AUTOSAR XML (schema 4-2-2)
standard types defined: void, boolean, float32, float64, sint16, sint32, sint64, sint8, uint16, uint32, uint64, uint8, sint16_least, sint32_least, sint8_least, uint16_least, uint32_least, uint8_least, Std_ReturnType
package /AUTOSAR/AUTOSAR_PhysicalUnits/PhysicalDimensions
  76 x physical dimension:
    Amnt1: length-exp=0, mass-exp=0, time-exp=0, current-exp=0, temperature-exp=0, molar-amount-exp=1, luminous-intensity-exp=0  # Quantity of substance
    I1: length-exp=0, mass-exp=0, time-exp=0, current-exp=1, temperature-exp=0, molar-amount-exp=0, luminous-intensity-exp=0  # Electric Current
    Illmn1: length-exp=0, mass-exp=0, time-exp=0, current-exp=0, temperature-exp=0, molar-amount-exp=0, luminous-intensity-exp=1  # Luminous intensity
    Len1: length-exp=1, mass-exp=0, time-exp=0, current-exp=0, temperature-exp=0, molar-amount-exp=0, luminous-intensity-exp=0  # Length
    Len1M1TiNeg2: length-exp=1, mass-exp=1, time-exp=-2, current-exp=0, temperature-exp=0, molar-amount-exp=0, luminous-intensity-exp=0  # Force
    Len1M1TiNeg2INeg2: length-exp=1, mass-exp=1, time-exp=-2, current-exp=-2, temperature-exp=0, molar-amount-exp=0, luminous-intensity-exp=0  # Permeability
    Len1M1TiNeg2_1: length-exp=1, mass-exp=1, time-exp=-2, current-exp=0, temperature-exp=0, molar-amount-exp=0, luminous-intensity-exp=0  # Electrical Energy Consumption
    Len1M1TiNeg3INeg1: length-exp=1, mass-exp=1, time-exp=-3, current-exp=-1, temperature-exp=0, molar-amount-exp=0, luminous-intensity-exp=0  # Electric Field Strength / Electric intensity
    Len1M1TiNeg3TNeg1: length-exp=1, mass-exp=1, time-exp=-3, current-exp=0, temperature-exp=-1, molar-amount-exp=0, luminous-intensity-exp=0  # Thermal Conductivity
    Len1TiNeg1: length-exp=1, mass-exp=0, time-exp=-1, current-exp=0, temperature-exp=0, molar-amount-exp=0, luminous-intensity-exp=0  # Velocity
    Len1TiNeg2: length-exp=1, mass-exp=0, time-exp=-2, current-exp=0, temperature-exp=0, molar-amount-exp=0, luminous-intensity-exp=0  # Acceleration
    Len1TiNeg3: length-exp=1, mass-exp=0, time-exp=-3, current-exp=0, temperature-exp=0, molar-amount-exp=0, luminous-intensity-exp=0  # Acceleration Time Gradient
    Len2: length-exp=2, mass-exp=0, time-exp=0, current-exp=0, temperature-exp=0, molar-amount-exp=0, luminous-intensity-exp=0  # Area
    Len2M1: length-exp=2, mass-exp=1, time-exp=0, current-exp=0, temperature-exp=0, molar-amount-exp=0, luminous-intensity-exp=0  # Moment of Inertia
    Len2M1TiNeg1: length-exp=2, mass-exp=1, time-exp=-1, current-exp=0, temperature-exp=0, molar-amount-exp=0, luminous-intensity-exp=0  # Angular Momentum
    Len2M1TiNeg2: length-exp=2, mass-exp=1, time-exp=-2, current-exp=0, temperature-exp=0, molar-amount-exp=0, luminous-intensity-exp=0  # Torque
    Len2M1TiNeg2AmntNeg1: length-exp=2, mass-exp=1, time-exp=-2, current-exp=0, temperature-exp=0, molar-amount-exp=-1, luminous-intensity-exp=0  # Molar Energy
    Len2M1TiNeg2INeg1: length-exp=2, mass-exp=1, time-exp=-2, current-exp=-1, temperature-exp=0, molar-amount-exp=0, luminous-intensity-exp=0  # Magnetic Flux
    Len2M1TiNeg2INeg2: length-exp=2, mass-exp=1, time-exp=-2, current-exp=-2, temperature-exp=0, molar-amount-exp=0, luminous-intensity-exp=0  # Inductance
    Len2M1TiNeg2TNeg1: length-exp=2, mass-exp=1, time-exp=-2, current-exp=0, temperature-exp=-1, molar-amount-exp=0, luminous-intensity-exp=0  # Heat Capacity
    Len2M1TiNeg2TNeg1AmntNeg1: length-exp=2, mass-exp=1, time-exp=-2, current-exp=0, temperature-exp=-1, molar-amount-exp=-1, luminous-intensity-exp=0  # Molar Heat Capacity
    Len2M1TiNeg2_1: length-exp=2, mass-exp=1, time-exp=-2, current-exp=0, temperature-exp=0, molar-amount-exp=0, luminous-intensity-exp=0  # Energy
    Len2M1TiNeg3: length-exp=2, mass-exp=1, time-exp=-3, current-exp=0, temperature-exp=0, molar-amount-exp=0, luminous-intensity-exp=0  # Torque Time Gradient
    Len2M1TiNeg3INeg1: length-exp=2, mass-exp=1, time-exp=-3, current-exp=-1, temperature-exp=0, molar-amount-exp=0, luminous-intensity-exp=0  # Voltage
    Len2M1TiNeg3INeg2: length-exp=2, mass-exp=1, time-exp=-3, current-exp=-2, temperature-exp=0, molar-amount-exp=0, luminous-intensity-exp=0  # Electric Resistance
    Len2M1TiNeg3_1: length-exp=2, mass-exp=1, time-exp=-3, current-exp=0, temperature-exp=0, molar-amount-exp=0, luminous-intensity-exp=0  # Power
    Len2M1TiNeg4: length-exp=2, mass-exp=1, time-exp=-4, current-exp=0, temperature-exp=0, molar-amount-exp=0, luminous-intensity-exp=0  # Power Time Gradient
    Len2M1TiNeg4INeg1: length-exp=2, mass-exp=1, time-exp=-4, current-exp=-1, temperature-exp=0, molar-amount-exp=0, luminous-intensity-exp=0  # Voltage Time Gradient
    Len2Ti1: length-exp=2, mass-exp=0, time-exp=-1, current-exp=0, temperature-exp=0, molar-amount-exp=0, luminous-intensity-exp=0  # Kinematic Viscosity
    Len2TiNeg2: length-exp=2, mass-exp=0, time-exp=-2, current-exp=0, temperature-exp=0, molar-amount-exp=0, luminous-intensity-exp=0  # Specific Heat
    Len2TiNeg2TNeg1: length-exp=2, mass-exp=0, time-exp=-2, current-exp=0, temperature-exp=-1, molar-amount-exp=0, luminous-intensity-exp=0  # Specific Heat Capacity
    Len2_1: length-exp=2, mass-exp=0, time-exp=0, current-exp=0, temperature-exp=0, molar-amount-exp=0, luminous-intensity-exp=0  # Volume Per Distance / Fuel Consumption
    Len3: length-exp=3, mass-exp=0, time-exp=0, current-exp=0, temperature-exp=0, molar-amount-exp=0, luminous-intensity-exp=0  # Volume
    Len3MNeg1: length-exp=3, mass-exp=-1, time-exp=0, current-exp=0, temperature-exp=0, molar-amount-exp=0, luminous-intensity-exp=0  # Specific Volume
    Len3TiNeg1: length-exp=3, mass-exp=0, time-exp=-1, current-exp=0, temperature-exp=0, molar-amount-exp=0, luminous-intensity-exp=0  # Volumetric Flow
    Len3TiNeg2: length-exp=3, mass-exp=0, time-exp=-2, current-exp=0, temperature-exp=0, molar-amount-exp=0, luminous-intensity-exp=0  # Volumetric Flow Gradient
    LenNeg1: length-exp=-1, mass-exp=0, time-exp=0, current-exp=0, temperature-exp=0, molar-amount-exp=0, luminous-intensity-exp=0  # Inverse Length
    LenNeg1M1TiNeg1: length-exp=-1, mass-exp=1, time-exp=-1, current-exp=0, temperature-exp=0, molar-amount-exp=0, luminous-intensity-exp=0  # Dynamic Viscosity
    LenNeg1M1TiNeg2: length-exp=-1, mass-exp=1, time-exp=-2, current-exp=0, temperature-exp=0, molar-amount-exp=0, luminous-intensity-exp=0  # Pressure
    LenNeg1M1TiNeg2_1: length-exp=-1, mass-exp=1, time-exp=-2, current-exp=0, temperature-exp=0, molar-amount-exp=0, luminous-intensity-exp=0  # Pressure by Angle
    LenNeg1M1TiNeg3: length-exp=-1, mass-exp=1, time-exp=-3, current-exp=0, temperature-exp=0, molar-amount-exp=0, luminous-intensity-exp=0  # Pressure Gradient
    LenNeg2Illmn1: length-exp=-2, mass-exp=0, time-exp=0, current-exp=0, temperature-exp=0, molar-amount-exp=0, luminous-intensity-exp=1  # Illuminance
    LenNeg2MNeg1Ti3I2: length-exp=-2, mass-exp=-1, time-exp=3, current-exp=2, temperature-exp=0, molar-amount-exp=0, luminous-intensity-exp=0  # Electrical Conductance
    LenNeg2MNeg1Ti4I2: length-exp=-2, mass-exp=-1, time-exp=4, current-exp=2, temperature-exp=0, molar-amount-exp=0, luminous-intensity-exp=0  # Capacitance
    LenNeg3Amnt1: length-exp=-3, mass-exp=0, time-exp=0, current-exp=0, temperature-exp=0, molar-amount-exp=1, luminous-intensity-exp=0  # Concentration
    LenNeg3M1: length-exp=-3, mass-exp=1, time-exp=0, current-exp=0, temperature-exp=0, molar-amount-exp=0, luminous-intensity-exp=0  # Mass Density
    LenNeg3MNeg1Ti2I2: length-exp=-3, mass-exp=-1, time-exp=2, current-exp=2, temperature-exp=0, molar-amount-exp=0, luminous-intensity-exp=0  # Electrical Conductivity Gradient
    LenNeg3MNeg1Ti3I2: length-exp=-3, mass-exp=-1, time-exp=3, current-exp=2, temperature-exp=0, molar-amount-exp=0, luminous-intensity-exp=0  # Electrical Conductivity
    LenNeg3Ti1I1: length-exp=-3, mass-exp=0, time-exp=1, current-exp=1, temperature-exp=0, molar-amount-exp=0, luminous-intensity-exp=0  # Electric Charge Density
    LenNeg3Ti1I1_1: length-exp=-3, mass-exp=0, time-exp=1, current-exp=1, temperature-exp=0, molar-amount-exp=0, luminous-intensity-exp=0  # Pressure per Voltage
    LenNeg3TiNeg1Amnt1: length-exp=-3, mass-exp=0, time-exp=-1, current-exp=0, temperature-exp=0, molar-amount-exp=1, luminous-intensity-exp=0  # Reaction Rate
    LenNeg4M1TiNeg1: length-exp=-4, mass-exp=1, time-exp=-1, current-exp=0, temperature-exp=0, molar-amount-exp=0, luminous-intensity-exp=0  # Pressure per Volumetric Flow / Flow Resistance
    M1: length-exp=0, mass-exp=1, time-exp=0, current-exp=0, temperature-exp=0, molar-amount-exp=0, luminous-intensity-exp=0  # Mass
    M1AmntNeg1: length-exp=0, mass-exp=1, time-exp=0, current-exp=0, temperature-exp=0, molar-amount-exp=-1, luminous-intensity-exp=0  # Molar Mass
    M1TiNeg1: length-exp=0, mass-exp=1, time-exp=-1, current-exp=0, temperature-exp=0, molar-amount-exp=0, luminous-intensity-exp=0  # Mass Flow
    M1TiNeg1_1: length-exp=0, mass-exp=1, time-exp=-1, current-exp=0, temperature-exp=0, molar-amount-exp=0, luminous-intensity-exp=0  # Translational Dumping
    M1TiNeg2: length-exp=0, mass-exp=1, time-exp=-2, current-exp=0, temperature-exp=0, molar-amount-exp=0, luminous-intensity-exp=0  # Surface Tension
    M1TiNeg2INeg1: length-exp=0, mass-exp=1, time-exp=-2, current-exp=-1, temperature-exp=0, molar-amount-exp=0, luminous-intensity-exp=0  # Magnetic Flux Density, Magnetic Induction
    M1TiNeg3TNeg1: length-exp=0, mass-exp=1, time-exp=-3, current-exp=0, temperature-exp=-1, molar-amount-exp=0, luminous-intensity-exp=0  # Heat Transfer Coefficient
    NoDimension: length-exp=0, mass-exp=0, time-exp=0, current-exp=0, temperature-exp=0, molar-amount-exp=0, luminous-intensity-exp=0  # Dimensionless
    NoDimension_1: length-exp=0, mass-exp=0, time-exp=0, current-exp=0, temperature-exp=0, molar-amount-exp=0, luminous-intensity-exp=0  # Ratio
    NoDimension_2: length-exp=0, mass-exp=0, time-exp=0, current-exp=0, temperature-exp=0, molar-amount-exp=0, luminous-intensity-exp=0  # Angle
    NoDimension_5: length-exp=0, mass-exp=0, time-exp=0, current-exp=0, temperature-exp=0, molar-amount-exp=0, luminous-intensity-exp=0  # Logarithmic Ratio
    NoDimension_6: length-exp=0, mass-exp=0, time-exp=0, current-exp=0, temperature-exp=0, molar-amount-exp=0, luminous-intensity-exp=0  # Amount of Data
    T1: length-exp=0, mass-exp=0, time-exp=0, current-exp=0, temperature-exp=1, molar-amount-exp=0, luminous-intensity-exp=0  # Absolute Temperature
    T1I1: length-exp=0, mass-exp=0, time-exp=1, current-exp=1, temperature-exp=0, molar-amount-exp=0, luminous-intensity-exp=0  # Electric Charge
    T1_1: length-exp=0, mass-exp=0, time-exp=0, current-exp=0, temperature-exp=1, molar-amount-exp=0, luminous-intensity-exp=0  # Relative Temperature, Temperature Difference
    Ti1: length-exp=0, mass-exp=0, time-exp=1, current-exp=0, temperature-exp=0, molar-amount-exp=0, luminous-intensity-exp=0  # Time
    TiNeg1: length-exp=0, mass-exp=0, time-exp=-1, current-exp=0, temperature-exp=0, molar-amount-exp=0, luminous-intensity-exp=0  # Frequency
    TiNeg1Amnt1: length-exp=0, mass-exp=0, time-exp=-1, current-exp=0, temperature-exp=0, molar-amount-exp=1, luminous-intensity-exp=0  # Catalytic Activity
    TiNeg1I1: length-exp=0, mass-exp=0, time-exp=-1, current-exp=1, temperature-exp=0, molar-amount-exp=0, luminous-intensity-exp=0  # Electric Current Gradient
    TiNeg1T1: length-exp=0, mass-exp=0, time-exp=-1, current-exp=0, temperature-exp=1, molar-amount-exp=0, luminous-intensity-exp=0  # Temperature Gradient
    TiNeg1_1: length-exp=0, mass-exp=0, time-exp=-1, current-exp=0, temperature-exp=0, molar-amount-exp=0, luminous-intensity-exp=0  # Ratio Gradient
    TiNeg1_2: length-exp=0, mass-exp=0, time-exp=-1, current-exp=0, temperature-exp=0, molar-amount-exp=0, luminous-intensity-exp=0  # Rotational Speed
    TiNeg1_3: length-exp=0, mass-exp=0, time-exp=-1, current-exp=0, temperature-exp=0, molar-amount-exp=0, luminous-intensity-exp=0  # Transfer Rate
    TiNeg2: length-exp=0, mass-exp=0, time-exp=-2, current-exp=0, temperature-exp=0, molar-amount-exp=0, luminous-intensity-exp=0  # Rotational Speed Gradient
package /AUTOSAR/AUTOSAR_PhysicalUnits/Units
  164 x unit:
    Ampr: display-name=A, factor-si-to-unit=1, offset-si-to-unit=0, physical-dimension=I1  # Ampere
    AmprPerSec: display-name=A/s, factor-si-to-unit=1, offset-si-to-unit=0, physical-dimension=TiNeg1I1  # Ampere Per Second
    AmprSec: display-name=As, factor-si-to-unit=1, offset-si-to-unit=0, physical-dimension=T1I1  # Amperesecond
    Bar: display-name=bar, factor-si-to-unit=1E-05, offset-si-to-unit=0, physical-dimension=LenNeg1M1TiNeg2
    BarPerSec: display-name=bar/s, factor-si-to-unit=1E-05, offset-si-to-unit=0, physical-dimension=LenNeg1M1TiNeg3  # Bar Per Second
    Bel: display-name=B, factor-si-to-unit=1, offset-si-to-unit=0, physical-dimension=NoDimension_5
    Bit: display-name=bit, factor-si-to-unit=1, offset-si-to-unit=0, physical-dimension=NoDimension_6
    BitPerSec: display-name=bit/s, factor-si-to-unit=1, offset-si-to-unit=0, physical-dimension=TiNeg1_3  # Bit Per Second
    BytPerSec: display-name=Byte/s, factor-si-to-unit=0.125, offset-si-to-unit=0, physical-dimension=TiNeg1_3  # Byte Per Second
    Byte: display-name=Byte, factor-si-to-unit=0.125, offset-si-to-unit=0, physical-dimension=NoDimension_6
    Cd: display-name=cd, factor-si-to-unit=1, offset-si-to-unit=0, physical-dimension=Illmn1  # Candela
    CentiMtr: display-name=cm, factor-si-to-unit=100, offset-si-to-unit=0, physical-dimension=Len1  # Centimeter
    CentiMtrSqd: display-name=cm^2, factor-si-to-unit=10000, offset-si-to-unit=0, physical-dimension=Len2  # Square Centimeter
    Coulomb: display-name=C, factor-si-to-unit=1, offset-si-to-unit=0, physical-dimension=T1I1
    Day: display-name=d, factor-si-to-unit=1.15740740740741E-05, offset-si-to-unit=0, physical-dimension=Ti1
    DeciBel: display-name=dB, factor-si-to-unit=10, offset-si-to-unit=0, physical-dimension=NoDimension_5  # Decibel
    Deg: display-name=°, factor-si-to-unit=360, offset-si-to-unit=0, physical-dimension=NoDimension_2  # Degree
    DegCgrd: display-name=°C, factor-si-to-unit=1, offset-si-to-unit=-273.15, physical-dimension=T1  # Degree Celsius (Absolute Temperature)
    DegPerSec: display-name=°/s, factor-si-to-unit=360, offset-si-to-unit=0, physical-dimension=TiNeg1_2  # Degree Per Sec
    Frd: display-name=F, factor-si-to-unit=1, offset-si-to-unit=0, physical-dimension=LenNeg2MNeg1Ti4I2  # Farad
    Gr: display-name=g, factor-si-to-unit=1000, offset-si-to-unit=0, physical-dimension=M1  # Gram
    GrPerLtr: display-name=g/l, factor-si-to-unit=1, offset-si-to-unit=0, physical-dimension=LenNeg3M1  # Gram Per Liter
    GrPerMol: display-name=g/mol, factor-si-to-unit=1000, offset-si-to-unit=0, physical-dimension=M1AmntNeg1  # Gram Per Mole
    GrPerSec: display-name=g/s, factor-si-to-unit=1000, offset-si-to-unit=0, physical-dimension=M1TiNeg1  # Gram Per Second
    HectoPa: display-name=hPa, factor-si-to-unit=0.01, offset-si-to-unit=0, physical-dimension=LenNeg1M1TiNeg2  # Hectopascal
    HectoPaPerSec: display-name=hPa/s, factor-si-to-unit=0.01, offset-si-to-unit=0, physical-dimension=LenNeg1M1TiNeg3  # Hectopascal Per Second
    HectoPaPerVolt: display-name=hPa/V, factor-si-to-unit=0.01, offset-si-to-unit=0, physical-dimension=LenNeg3Ti1I1_1  # Hectopascal Per Volt
    HectoPaSecPerMtrCubd: display-name=hPa/((m^3)/s), factor-si-to-unit=0.01, offset-si-to-unit=0, physical-dimension=LenNeg4M1TiNeg1  # Hectopascal Per Cubic Meter Per Second
    Henry: display-name=H, factor-si-to-unit=1, offset-si-to-unit=0, physical-dimension=Len2M1TiNeg2INeg2
    HenryPerMtr: display-name=H/m, factor-si-to-unit=1, offset-si-to-unit=0, physical-dimension=Len1M1TiNeg2INeg2  # Henry Per Meter
    Hr: display-name=h, factor-si-to-unit=0.000277777777777778, offset-si-to-unit=0, physical-dimension=Ti1  # Hour
    Hz: display-name=Hz, factor-si-to-unit=1, offset-si-to-unit=0, physical-dimension=TiNeg1  # Hertz
    Jou: display-name=J, factor-si-to-unit=1, offset-si-to-unit=0, physical-dimension=Len2M1TiNeg2_1  # Joule
    JouPerKelvin: display-name=J/K, factor-si-to-unit=1, offset-si-to-unit=0, physical-dimension=Len2M1TiNeg2TNeg1  # Joule Per Kelvin
    JouPerKiloGr: display-name=J/kg, factor-si-to-unit=1, offset-si-to-unit=0, physical-dimension=Len2TiNeg2  # Joule Per Kilogram
    JouPerKiloGrPerKelvin: display-name=J/(kg*K), factor-si-to-unit=1, offset-si-to-unit=0, physical-dimension=Len2TiNeg2TNeg1  # Joule Per Kilogram Per Kelvin
    JouPerMol: display-name=J/mol, factor-si-to-unit=1, offset-si-to-unit=0, physical-dimension=Len2M1TiNeg2AmntNeg1  # Joule Per Mole
    JouPerMolPerKelvin: display-name=J/(mol*K), factor-si-to-unit=1, offset-si-to-unit=0, physical-dimension=Len2M1TiNeg2TNeg1AmntNeg1  # Joule Per Mole Per Kelvin
    Kat: display-name=kat, factor-si-to-unit=1, offset-si-to-unit=0, physical-dimension=TiNeg1Amnt1  # Katal
    KelvinAbslt: display-name=K, factor-si-to-unit=1, offset-si-to-unit=0, physical-dimension=T1  # Kelvin (Absolute Temperature)
    KelvinPerSec: display-name=K/s, factor-si-to-unit=1, offset-si-to-unit=0, physical-dimension=TiNeg1T1  # Kelvin Per Second
    KelvinRel: display-name=K, factor-si-to-unit=1, offset-si-to-unit=0, physical-dimension=T1_1  # Kelvin (Relative Temperature, Temperature Difference)
    KiloBitPerSec: display-name=kbit/s, factor-si-to-unit=0.001, offset-si-to-unit=0, physical-dimension=TiNeg1_3  # Kilobit Per Second
    KiloGr: display-name=kg, factor-si-to-unit=1, offset-si-to-unit=0, physical-dimension=M1  # Kilogram
    KiloGrPerHr: display-name=kg/h, factor-si-to-unit=3600, offset-si-to-unit=0, physical-dimension=M1TiNeg1  # Kilogram Per Hour
    KiloGrPerMtrCubd: display-name=kg/(m^3), factor-si-to-unit=1, offset-si-to-unit=0, physical-dimension=LenNeg3M1  # Kilogram Per Cubic Meter
    KiloGrPerSec: display-name=kg/s, factor-si-to-unit=1, offset-si-to-unit=0, physical-dimension=M1TiNeg1  # Kilogram Per Second
    KiloGrSqrMtr: display-name=kg*(m^2), factor-si-to-unit=1, offset-si-to-unit=0, physical-dimension=Len2M1  # Kilogram Square Meter
    KiloHz: display-name=kHz, factor-si-to-unit=0.001, offset-si-to-unit=0, physical-dimension=TiNeg1  # Kilohertz
    KiloJou: display-name=kJ, factor-si-to-unit=0.001, offset-si-to-unit=0, physical-dimension=Len2M1TiNeg2_1  # Kilojoule
    KiloMtr: display-name=km, factor-si-to-unit=0.001, offset-si-to-unit=0, physical-dimension=Len1  # Kilometer
    KiloMtrPerHr: display-name=km/h, factor-si-to-unit=3.6, offset-si-to-unit=0, physical-dimension=Len1TiNeg1  # Kilometer Per Hour
    KiloMtrPerHrPerSec: display-name=(km/h)/s, factor-si-to-unit=3.6, offset-si-to-unit=0, physical-dimension=Len1TiNeg2  # Kilometer Per Hour Per Second
    KiloNwt: display-name=kN, factor-si-to-unit=0.001, offset-si-to-unit=0, physical-dimension=Len1M1TiNeg2  # Kilonewton
    KiloNwtMtrPerSec: display-name=(kN*m)/s, factor-si-to-unit=0.001, offset-si-to-unit=0, physical-dimension=Len2M1TiNeg3  # Kilonewtonmeter Per Second
    KiloOhm: display-name=kΩ, factor-si-to-unit=0.001, offset-si-to-unit=0, physical-dimension=Len2M1TiNeg3INeg2  # Kiloohm
    KiloVolt: display-name=kV, factor-si-to-unit=0.001, offset-si-to-unit=0, physical-dimension=Len2M1TiNeg3INeg1  # Kilovolt
    KiloWatt: display-name=kW, factor-si-to-unit=0.001, offset-si-to-unit=0, physical-dimension=Len2M1TiNeg3_1  # Kilowatt
    KiloWattHr: display-name=kWh, factor-si-to-unit=2.77777777777778E-07, offset-si-to-unit=0, physical-dimension=Len2M1TiNeg2_1  # Kilowatthour
    KiloWattHrPer100KiloMtr: display-name=kWh/(100*km), factor-si-to-unit=0.0277777777777778, offset-si-to-unit=0, physical-dimension=Len1M1TiNeg2_1  # Kilowatthour Per 100 Kilometer
    Ltr: display-name=l, factor-si-to-unit=1000, offset-si-to-unit=0, physical-dimension=Len3  # Liter
    LtrPer100KiloMtr: display-name=l/(100km), factor-si-to-unit=100000000, offset-si-to-unit=0, physical-dimension=Len2_1  # Liter Per 100 Kilometer
    LtrPerHr: display-name=l/h, factor-si-to-unit=3600000, offset-si-to-unit=0, physical-dimension=Len3TiNeg1  # Liter Per Hour
    LtrPerKiloMtr: display-name=l/km, factor-si-to-unit=1000000, offset-si-to-unit=0, physical-dimension=Len2_1  # Liter Per Kilometer
    MegaBitPerSec: display-name=Mbit/s, factor-si-to-unit=1E-06, offset-si-to-unit=0, physical-dimension=TiNeg1_3  # Megabit Per Second
    MegaHz: display-name=MHz, factor-si-to-unit=1E-06, offset-si-to-unit=0, physical-dimension=TiNeg1  # Megahertz
    MegaJou: display-name=MJ, factor-si-to-unit=1E-06, offset-si-to-unit=0, physical-dimension=Len2M1TiNeg2_1  # Megajoule
    MegaOhm: display-name=MΩ, factor-si-to-unit=1E-06, offset-si-to-unit=0, physical-dimension=Len2M1TiNeg3INeg2  # Megaohm
    MegaPa: display-name=MPa, factor-si-to-unit=1E-06, offset-si-to-unit=0, physical-dimension=LenNeg1M1TiNeg2  # Megapascal
    MegaWatt: display-name=MW, factor-si-to-unit=1E-06, offset-si-to-unit=0, physical-dimension=Len2M1TiNeg3_1  # Megawatt
    MicroAmpr: display-name=µA, factor-si-to-unit=1000000, offset-si-to-unit=0, physical-dimension=I1  # Microampere
    MicroFrd: display-name=µF, factor-si-to-unit=1000000, offset-si-to-unit=0, physical-dimension=LenNeg2MNeg1Ti4I2  # Microfarad
    MicroGr: display-name=µg, factor-si-to-unit=1000000000, offset-si-to-unit=0, physical-dimension=M1  # Microgram
    MicroJou: display-name=µJ, factor-si-to-unit=1000000, offset-si-to-unit=0, physical-dimension=Len2M1TiNeg2_1  # Microjoule
    MicroLtr: display-name=µl, factor-si-to-unit=1000000000, offset-si-to-unit=0, physical-dimension=Len3  # Microliter
    MicroLtrPerSec: display-name=µl/s, factor-si-to-unit=1000000000, offset-si-to-unit=0, physical-dimension=Len3TiNeg1  # Microliter Per Second
    MicroMtr: display-name=µm, factor-si-to-unit=1000000, offset-si-to-unit=0, physical-dimension=Len1  # Micrometer
    MicroSec: display-name=µs, factor-si-to-unit=1000000, offset-si-to-unit=0, physical-dimension=Ti1  # Microsecond
    MicroTesla: display-name=µT, factor-si-to-unit=1000000, offset-si-to-unit=0, physical-dimension=M1TiNeg2INeg1  # Microtesla
    MilliAmpr: display-name=mA/s, factor-si-to-unit=1000, offset-si-to-unit=0, physical-dimension=I1  # Milliampere
    MilliAmprPerSec: display-name=mA/s, factor-si-to-unit=1000, offset-si-to-unit=0, physical-dimension=TiNeg1I1  # Milliampere Per Second
    MilliBar: display-name=mbar, factor-si-to-unit=0.01, offset-si-to-unit=0, physical-dimension=LenNeg1M1TiNeg2  # Millibar
    MilliFrd: display-name=mF, factor-si-to-unit=1000, offset-si-to-unit=0, physical-dimension=LenNeg2MNeg1Ti4I2  # Millifarad
    MilliGr: display-name=mg, factor-si-to-unit=1000000, offset-si-to-unit=0, physical-dimension=M1  # Milligram
    MilliGrPerSec: display-name=mg/s, factor-si-to-unit=1000000, offset-si-to-unit=0, physical-dimension=M1TiNeg1  # Milligram Per Second
    MilliJou: display-name=mJ, factor-si-to-unit=1000, offset-si-to-unit=0, physical-dimension=Len2M1TiNeg2_1  # Millijoule
    MilliLtr: display-name=ml, factor-si-to-unit=1000000, offset-si-to-unit=0, physical-dimension=Len3  # Milliliter
    MilliMtr: display-name=mm, factor-si-to-unit=1000, offset-si-to-unit=0, physical-dimension=Len1  # Millimeter
    MilliMtrCubd: display-name=mm^3, factor-si-to-unit=1000000000, offset-si-to-unit=0, physical-dimension=Len3  # Cubic Millimeter
    MilliMtrCubdPerSec: display-name=(mm^3)/s, factor-si-to-unit=1000000000, offset-si-to-unit=0, physical-dimension=Len3TiNeg1  # Cubic Millimeter Per Second
    MilliOhm: display-name=mΩ, factor-si-to-unit=1000, offset-si-to-unit=0, physical-dimension=Len2M1TiNeg3INeg2  # Milliohm
    MilliSec: display-name=ms, factor-si-to-unit=1000, offset-si-to-unit=0, physical-dimension=Ti1  # Millisecond
    MilliTesla: display-name=mT, factor-si-to-unit=1000, offset-si-to-unit=0, physical-dimension=M1TiNeg2INeg1  # Millitesla
    MilliVolt: display-name=mV, factor-si-to-unit=1000, offset-si-to-unit=0, physical-dimension=Len2M1TiNeg3INeg1  # Millivolt
    MilliVoltPerSec: display-name=mV/s, factor-si-to-unit=1000, offset-si-to-unit=0, physical-dimension=Len2M1TiNeg4INeg1  # Millivolt Per Second
    MilliWatt: display-name=mW, factor-si-to-unit=1000, offset-si-to-unit=0, physical-dimension=Len2M1TiNeg3_1  # Milliwatt
    Mins: display-name=min, factor-si-to-unit=0.0166666666666667, offset-si-to-unit=0, physical-dimension=Ti1  # Minute
    Ml: display-name=mile, factor-si-to-unit=0.000621371192237333, offset-si-to-unit=0, physical-dimension=Len1  # Mile
    MlPerHr: display-name=mph, factor-si-to-unit=2.2369362920544, offset-si-to-unit=0, physical-dimension=Len1TiNeg1  # Miles Per Hour
    Mol: display-name=mol, factor-si-to-unit=1, offset-si-to-unit=0, physical-dimension=Amnt1  # Mole
    MolPerLtr: display-name=mol/l, factor-si-to-unit=0.001, offset-si-to-unit=0, physical-dimension=LenNeg3Amnt1  # Mole Per Liter
    MolPerLtrPerSec: display-name=(mol/l)/s, factor-si-to-unit=0.001, offset-si-to-unit=0, physical-dimension=LenNeg3TiNeg1Amnt1  # Mol Per Liter Per Second
    MolPerMtrCubd: display-name=mol/(m^3), factor-si-to-unit=1, offset-si-to-unit=0, physical-dimension=LenNeg3Amnt1  # Mole Per Cubic Meter
    MolPerSec: display-name=mol/s, factor-si-to-unit=1, offset-si-to-unit=0, physical-dimension=TiNeg1Amnt1  # Mole Per Second
    Mtr: display-name=m, factor-si-to-unit=1, offset-si-to-unit=0, physical-dimension=Len1  # Meter
    MtrCubd: display-name=m^3, factor-si-to-unit=1, offset-si-to-unit=0, physical-dimension=Len3  # Cubic Meter
    MtrCubdPerHr: display-name=(m^3)/h, factor-si-to-unit=3600, offset-si-to-unit=0, physical-dimension=Len3TiNeg1  # Cubic Meter Per Hour
    MtrCubdPerHrPerSec: display-name=(m^3)/(h*s), factor-si-to-unit=3600, offset-si-to-unit=0, physical-dimension=Len3TiNeg2  # Cubic Meter Per Hour Per Second
    MtrCubdPerKiloGr: display-name=(m^3)/kg, factor-si-to-unit=1, offset-si-to-unit=0, physical-dimension=Len3MNeg1  # Cubic Meter Per Kilogram
    MtrPerSec: display-name=m/s, factor-si-to-unit=1, offset-si-to-unit=0, physical-dimension=Len1TiNeg1  # Meter Per Second
    MtrPerSecCubd: display-name=m/(s^3), factor-si-to-unit=1, offset-si-to-unit=0, physical-dimension=Len1TiNeg3  # Meter Per Cubic Second
    MtrPerSecSqd: display-name=m/(s^2), factor-si-to-unit=1, offset-si-to-unit=0, physical-dimension=Len1TiNeg2  # Meter Per Square Second
    MtrSqd: display-name=m^2, factor-si-to-unit=1, offset-si-to-unit=0, physical-dimension=Len2  # Square Meter
    MtrSqdPerSec: display-name=(m^2)/s, factor-si-to-unit=1, offset-si-to-unit=0, physical-dimension=Len2Ti1  # Square Meter Per Second
    NanoFrd: display-name=nF, factor-si-to-unit=1000000000, offset-si-to-unit=0, physical-dimension=LenNeg2MNeg1Ti4I2  # Nanofarad
    NanoSec: display-name=ns, factor-si-to-unit=1000000000, offset-si-to-unit=0, physical-dimension=Ti1  # Nanosecond
    NoUnit: display-name=-, factor-si-to-unit=1, offset-si-to-unit=0, physical-dimension=NoDimension  # Neither Physical nor Mathematical Unit
    Nwt: display-name=N, factor-si-to-unit=1, offset-si-to-unit=0, physical-dimension=Len1M1TiNeg2  # Newton
    NwtMtr: display-name=Nm, factor-si-to-unit=1, offset-si-to-unit=0, physical-dimension=Len2M1TiNeg2  # Newtonmeter
    NwtMtrPerRpm: display-name=Nm/rpm, factor-si-to-unit=0.0166666666666667, offset-si-to-unit=0, physical-dimension=Len2M1TiNeg1  # Newtonmeter Per Rpm
    NwtMtrPerRpmPerSec: display-name=Nm/(rpm/s), factor-si-to-unit=0.0166666666666667, offset-si-to-unit=0, physical-dimension=Len2M1  # Newtonmeter Per Rpm Per Second
    NwtMtrPerSec: display-name=(N*m)/s, factor-si-to-unit=1, offset-si-to-unit=0, physical-dimension=Len2M1TiNeg3  # Newtonmeter Per Second
    NwtMtrSec: display-name=Nm*s, factor-si-to-unit=1, offset-si-to-unit=0, physical-dimension=Len2M1TiNeg1  # Newtonmeter Second
    NwtMtrSqrSec: display-name=Nm*(s^2), factor-si-to-unit=1, offset-si-to-unit=0, physical-dimension=Len2M1  # Newtonmeter Square Second
    NwtPerMtr: display-name=N/m, factor-si-to-unit=1, offset-si-to-unit=0, physical-dimension=M1TiNeg2  # Newton Per Meter
    NwtSecPerMtr: display-name=Ns/m, factor-si-to-unit=1, offset-si-to-unit=0, physical-dimension=M1TiNeg1_1  # Newtonsecond Per Meter
    Ohm: display-name=Ω, factor-si-to-unit=1, offset-si-to-unit=0, physical-dimension=Len2M1TiNeg3INeg2
    Pa: display-name=Pa, factor-si-to-unit=1, offset-si-to-unit=0, physical-dimension=LenNeg1M1TiNeg2  # Pascal
    PaPerMtrCubdPerSec: display-name=Pa/((m^3)/s), factor-si-to-unit=1, offset-si-to-unit=0, physical-dimension=LenNeg4M1TiNeg1  # Pascal Per Cubic Meter Per Second
    PaPerSec: display-name=Pa/s, factor-si-to-unit=1, offset-si-to-unit=0, physical-dimension=LenNeg1M1TiNeg3  # Pascal Per Second
    PaSec: display-name=Pa*s, factor-si-to-unit=1, offset-si-to-unit=0, physical-dimension=LenNeg1M1TiNeg1  # Pascal Second
    PerMille: display-name=‰, factor-si-to-unit=1000, offset-si-to-unit=0, physical-dimension=NoDimension_1  # Permille
    PerMin: display-name=1/min, factor-si-to-unit=60, offset-si-to-unit=0, physical-dimension=TiNeg1_2  # Per Minute
    PerMtr: display-name=1/m, factor-si-to-unit=1, offset-si-to-unit=0, physical-dimension=LenNeg1  # Per Meter
    PerSec: display-name=1/s, factor-si-to-unit=1, offset-si-to-unit=0, physical-dimension=TiNeg1_2  # Per Second
    PerSecSqd: display-name=1/(s^2), factor-si-to-unit=1, offset-si-to-unit=0, physical-dimension=TiNeg2  # Per Square Second
    Perc: display-name=%, factor-si-to-unit=100, offset-si-to-unit=0, physical-dimension=NoDimension_1  # Percent
    PercPerMilliSec: display-name=%/ms, factor-si-to-unit=0.1, offset-si-to-unit=0, physical-dimension=TiNeg1_1  # Percent Per Millisecond
    PercPerSec: display-name=%/s, factor-si-to-unit=100, offset-si-to-unit=0, physical-dimension=TiNeg1_1  # Percent Per Second
    PicoFrd: display-name=pF, factor-si-to-unit=1000000000000, offset-si-to-unit=0, physical-dimension=LenNeg2MNeg1Ti4I2  # Picofarad
    PicoSec: display-name=ps, factor-si-to-unit=1000000000000, offset-si-to-unit=0, physical-dimension=Ti1  # Picosecond
    Ppm: display-name=ppm, factor-si-to-unit=1000000, offset-si-to-unit=0, physical-dimension=NoDimension_1  # Parts Per Million
    Rad: display-name=rad, factor-si-to-unit=6.28318530717958, offset-si-to-unit=0, physical-dimension=NoDimension_2  # Radian
    RadPerSec: display-name=rad/s, factor-si-to-unit=6.28318530717958, offset-si-to-unit=0, physical-dimension=TiNeg1_2  # Radian Per Second
    RadPerSecSqd: display-name=rad/(s^2), factor-si-to-unit=6.28318530717958, offset-si-to-unit=0, physical-dimension=TiNeg2  # Radian Per Square Second
    Rpm: display-name=rpm, factor-si-to-unit=60, offset-si-to-unit=0, physical-dimension=TiNeg1_2  # Revolutions Per Minute
    RpmPerSec: display-name=rpm/s, factor-si-to-unit=60, offset-si-to-unit=0, physical-dimension=TiNeg2  # Revolutions Per Minute Per Second
    S: display-name=S, factor-si-to-unit=1, offset-si-to-unit=0, physical-dimension=LenNeg2MNeg1Ti3I2  # Siemens
    SPerMtr: display-name=S/m, factor-si-to-unit=1, offset-si-to-unit=0, physical-dimension=LenNeg3MNeg1Ti3I2  # Siemens Per Meter
    SPerMtrPerSec: display-name=S/(m*s), factor-si-to-unit=1, offset-si-to-unit=0, physical-dimension=LenNeg3MNeg1Ti2I2  # Siemens Per Meter Per Second
    Sec: display-name=s, factor-si-to-unit=1, offset-si-to-unit=0, physical-dimension=Ti1  # Second
    Tesla: display-name=T, factor-si-to-unit=1, offset-si-to-unit=0, physical-dimension=M1TiNeg2INeg1
    Tonne: display-name=t, factor-si-to-unit=0.001, offset-si-to-unit=0, physical-dimension=M1
    Volt: display-name=V, factor-si-to-unit=1, offset-si-to-unit=0, physical-dimension=Len2M1TiNeg3INeg1
    VoltPerMilliSec: display-name=V/ms, factor-si-to-unit=0.001, offset-si-to-unit=0, physical-dimension=Len2M1TiNeg4INeg1  # Volt Per Millisecond
    VoltPerMtr: display-name=V/m, factor-si-to-unit=1, offset-si-to-unit=0, physical-dimension=Len1M1TiNeg3INeg1  # Volt Per Meter
    VoltPerSec: display-name=V/s, factor-si-to-unit=1, offset-si-to-unit=0, physical-dimension=Len2M1TiNeg4INeg1  # Volt Per Second
    Watt: display-name=W, factor-si-to-unit=1, offset-si-to-unit=0, physical-dimension=Len2M1TiNeg3_1
    WattPerKelvinPerMtrSqd: display-name=W/(K*m^2), factor-si-to-unit=1, offset-si-to-unit=0, physical-dimension=M1TiNeg3TNeg1  # Watt Per Kelvin Per Square Meter
    WattPerMtrPerKelvin: display-name=W/(m*K), factor-si-to-unit=1, offset-si-to-unit=0, physical-dimension=Len1M1TiNeg3TNeg1  # Watt Per Meter Per Kelvin
    WattPerSec: display-name=W/s, factor-si-to-unit=1, offset-si-to-unit=0, physical-dimension=Len2M1TiNeg4  # Watt Per Second
    WattSec: display-name=Ws, factor-si-to-unit=1, offset-si-to-unit=0, physical-dimension=Len2M1TiNeg2_1  # Wattsecond
    Wb: display-name=Wb, factor-si-to-unit=1, offset-si-to-unit=0, physical-dimension=Len2M1TiNeg2INeg1  # Weber
    Yr: display-name=a, factor-si-to-unit=3.16880878140289E-08, offset-si-to-unit=0, physical-dimension=Ti1  # Year
package /AUTOSAR/AUTOSAR_Platform/ImplementationDataTypes
  impl type ConstVoidPtr: category=DATA_REFERENCE, sw-pointer-target-props={target-category=VALUE, base-type=void, sw-impl-policy=CONST}, type-emitter=Platform_Types.h
  impl type VoidPtr: category=DATA_REFERENCE, sw-pointer-target-props={target-category=VALUE, base-type=void}, type-emitter=Platform_Types.h
package /AUTOSAR/AUTOSAR_Std/BswModuleEntrys
  bsw module entry Std_ExtractProtocolHeaderFieldsType: sw-service-impl-policy=STANDARD
    return type Std_ReturnType: implementation-data-type=Std_ReturnType
    4 x sw service arg:
      buffer: category=DATA_REFERENCE, direction=IN, sw-pointer-target-props={target-category=TYPE_REFERENCE, implementation-data-type=uint8, sw-impl-policy=CONST}
      bufferLength: direction=IN, implementation-data-type=uint32
      messageType: category=DATA_REFERENCE, direction=OUT, sw-pointer-target-props={target-category=TYPE_REFERENCE, implementation-data-type=Std_MessageTypeType}
      messageResult: category=DATA_REFERENCE, direction=OUT, sw-pointer-target-props={target-category=TYPE_REFERENCE, implementation-data-type=Std_MessageResultType}
package /AUTOSAR/AUTOSAR_Std/ImplementationDataTypes
  8 x impl type, all with type-emitter=Std_Types.h:
    Std_ExtractProtocolHeaderFieldsType: category=FUNCTION_REFERENCE, sw-pointer-target-props={target-category=FUNCTION_REFERENCE, function-pointer-signature=Std_ExtractProtocolHeaderFieldsType}  # Type for the function pointer to extract the relevant protocol header fields of the message and the type of the message result of a transformer. - At the time being, this is limited to the types used for C/S communication (i.e., REQUEST and RESPONSE and OK and ERROR).
    Std_MessageResultType: compu {0x00=STD_MESSAGERESULT_OK, 0x01=STD_MESSAGERESULT_ERROR}, range raw 0x00..0x02, implementation-data-type=uint8  # This type is used to encode different types of results for response messages. - Currently this encoding is limited to the distinction between OK and ERROR responses.
    Std_MessageTypeType: compu {0x00=STD_MESSAGETYPE_REQUEST, 0x01=STD_MESSAGETYPE_RESPONSE}, range raw 0x00..0x02, implementation-data-type=uint8  # This type is used to encode the different type of messages. - Currently this encoding is limited to the distinction between requests and responses in C/S communication.
    Std_TransformerClass: compu {0x00=STD_TRANSFORMER_UNSPECIFIED, 0x01=STD_TRANSFORMER_SERIALIZER, 0x02=STD_TRANSFORMER_SAFETY, 0x03=STD_TRANSFORMER_SECURITY, 0xFF=STD_TRANSFORMER_CUSTOM}, range raw 0x00..0xFF, implementation-data-type=uint8  # Std_TransformerClass is an enumeration where each element represents a transformer class.
    Std_TransformerError: category=STRUCTURE
      element errorCode: implementation-data-type=Std_TransformerErrorCode
      element transformerClass: implementation-data-type=Std_TransformerClass
    Std_TransformerErrorCode: range raw 0x00..0xFF, implementation-data-type=uint8  # The type of the Std_TransformerError.
    Std_TransformerForwardCode: compu {0x00=E_OK, 0x01=E_SAFETY_INVALID_REP, 0x02=E_SAFETY_INVALID_SEQ, 0x03=E_SAFETY_INVALID_CRC}, range raw 0x00..0x03, implementation-data-type=uint8
    Std_VersionInfoType: category=STRUCTURE  # This type shall be used to request the version of a BSW module using the <Module name>_GetVersionInfo() function.
      5 x element, all with category=TYPE_REFERENCE:
        vendorID: implementation-data-type=uint16
        moduleID: implementation-data-type=uint16
        sw_major_version: implementation-data-type=uint8
        sw_minor_version: implementation-data-type=uint8
        sw_patch_version: implementation-data-type=uint8
package /SharedElements/CompuMethods
  compu method CM_APCRCDWkUp: identical; unit m^2
  compu method CM_APCRCDWkUp: identical; unit m^2
  compu method CM_APCRCDWkUpqw: identical
  compu method CM_APCRCDWkUpqw: identical
  compu method CM_ActnOnErToMM: 3=ActnOnErToMM_MCBRecoverableError, 0=ActnOnErToMM_NoError, 1=ActnOnErToMM_Warning, 2=ActnOnErToMM_MCBRecoverableStandby, 4=ActnOnErToMM_MCBUnrecoverableError, 5=ActnOnErToMM_OBCNotReady, 6=ActnOnErToMM_OBCRecoverableError, 7=ActnOnErToMM_OBCUnrecoverableError; unit bit
  compu method CM_ActnOnErToMM: 3=ActnOnErToMM_MCBRecoverableError, 0=ActnOnErToMM_NoError, 1=ActnOnErToMM_Warning, 2=ActnOnErToMM_MCBRecoverableStandby, 4=ActnOnErToMM_MCBUnrecoverableError, 5=ActnOnErToMM_OBCNotReady, 6=ActnOnErToMM_OBCRecoverableError, 7=ActnOnErToMM_OBCUnrecoverableError; unit bit
package /SharedElements/DataConstr
  range DC_APCRCDWkUp: phys 0..96
  range DC_APCRCDWkUp: phys 0..96
  range DC_APCRCDWkUp1: phys 0..1
  range DC_APCRCDWkUp1: phys 0..1
  range DC_ActnOnErToMM: phys 0..7
  range DC_ActnOnErToMM: phys 0..7
package /SharedElements/PortInterfaces/SenderReceiver
  4 x sender receiver interface:
    CD_CrshSt_SR: invalidation-policy{data-element=CD_CrshSt_SR/PUBS, handle-invalid=DONT-INVALIDATE}
      data PUBS  # Turn switch sensor position [left, off, right]
    CD_CrshSt_SR: invalidation-policy{data-element=CHAdeMOS, handle-invalid=DONT-INVALIDATE}
      data CHAdeMOS  # Turn switch sensor position [left, off, right]
    CD_CrshSt_SR: invalidation-policy{data-element=PLS, handle-invalid=DONT-INVALIDATE}
      data PLS  # Turn switch sensor position [left, off, right]
    CD_CrshSt_SR: invalidation-policy{data-element=CD_CrshSt_SR/PUBS, handle-invalid=DONT-INVALIDATE}
      data PUBS  # Turn switch sensor position [left, off, right]
package /SwComponentTypes/ApplSWC
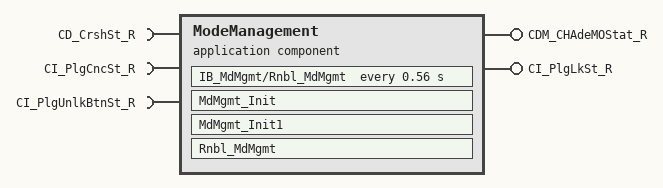
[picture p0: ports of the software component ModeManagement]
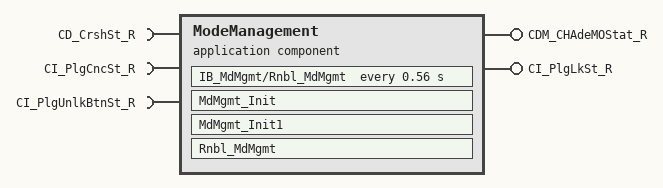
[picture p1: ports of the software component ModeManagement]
  application sw component type ModeManagement
    require port CD_CrshSt_R
    provide port CDM_CHAdeMOStat_R
    require port CI_PlgCncSt_R
    provide port CI_PlgLkSt_R
    require port CI_PlgUnlkBtnSt_R
    behavior IB_MdMgmt: handle-termination-and-restart=NO-SUPPORT
      constant-memorys:
        parameter data prototype PIP_test7: category=VALUE, sw-calibration-access=READ-WRITE, type=adt_max_count, init-value=constant-reference=ConstantSpecifications/CONST_PIP_test7
      static-memorys:
        data PIP_test6: category=VALUE, sw-calibration-access=READ-WRITE, type=adt_max_count, init-value=constant-reference=ConstantSpecifications/CONST_PIP_test6
      ar-typed-per-instance-memorys:
        data PIP_test5: category=VALUE, sw-calibration-access=READ-WRITE, type=adt_max_count, init-value=constant-reference=ConstantSpecifications/CONST_PIP_test5
      background event MdMgmt_InitEvent: start-on-event=IB_MdMgmt/MdMgmt_Init
      init event MdMgmt_InitEvent1: start-on-event=IB_MdMgmt/MdMgmt_Init1
      timing event MdMgmt10ms: start-on-event=IB_MdMgmt/Rnbl_MdMgmt, period=0.56
      explicit-inter-runnable-variables:
        data PIP_test3: category=VALUE, sw-calibration-access=READ-WRITE, type=adt_max_count, init-value=constant-reference=ConstantSpecifications/CONST_PIP_test3
      implicit-inter-runnable-variables:
        data PIP_test2: category=VALUE, sw-calibration-access=READ-WRITE, type=adt_max_count, init-value=constant-reference=ConstantSpecifications/CONST_PIP_test2
      per instance memory PIP_test4
      per-instance-parameters:
        parameter data prototype PIP_test1: category=VALUE, sw-calibration-access=READ-WRITE, type=adt_max_count, init-value=constant-reference=ConstantSpecifications/CONST_PIP_test1
      runnable MdMgmt_Init
      runnable MdMgmt_Init1
      runnable Rnbl_MdMgmt
      shared-parameters:
        parameter data prototype PIP_test0: category=VALUE, sw-calibration-access=READ-WRITE, type=adt_max_count, init-value=constant-reference=ConstantSpecifications/CONST_PIP_test0
    symbol props SymbolProps: symbol=ModeManagement
  application sw component type ModeManagement
    require port CD_CrshSt_R
    provide port CDM_CHAdeMOStat_R
    require port CI_PlgCncSt_R
    provide port CI_PlgLkSt_R
    require port CI_PlgUnlkBtnSt_R
    behavior IB_MdMgmt: handle-termination-and-restart=NO-SUPPORT
      constant-memorys:
        parameter data prototype PIP_test7: category=VALUE, sw-calibration-access=READ-WRITE, type=adt_max_count, init-value=constant-reference=ConstantSpecifications/CONST_PIP_test7
      static-memorys:
        data PIP_test6: category=VALUE, sw-calibration-access=READ-WRITE, type=adt_max_count, init-value=constant-reference=ConstantSpecifications/CONST_PIP_test6
      ar-typed-per-instance-memorys:
        data PIP_test5: category=VALUE, sw-calibration-access=READ-WRITE, type=adt_max_count, init-value=constant-reference=ConstantSpecifications/CONST_PIP_test5
      background event MdMgmt_InitEvent: start-on-event=IB_MdMgmt/MdMgmt_Init
      init event MdMgmt_InitEvent1: start-on-event=IB_MdMgmt/MdMgmt_Init1
      timing event MdMgmt10ms: start-on-event=IB_MdMgmt/Rnbl_MdMgmt, period=0.56
      explicit-inter-runnable-variables:
        data PIP_test3: category=VALUE, sw-calibration-access=READ-WRITE, type=adt_max_count, init-value=constant-reference=ConstantSpecifications/CONST_PIP_test3
      implicit-inter-runnable-variables:
        data PIP_test2: category=VALUE, sw-calibration-access=READ-WRITE, type=adt_max_count, init-value=constant-reference=ConstantSpecifications/CONST_PIP_test2
      per instance memory PIP_test4
      per-instance-parameters:
        parameter data prototype PIP_test1: category=VALUE, sw-calibration-access=READ-WRITE, type=adt_max_count, init-value=constant-reference=ConstantSpecifications/CONST_PIP_test1
      runnable MdMgmt_Init
      runnable MdMgmt_Init1
      runnable Rnbl_MdMgmt
      shared-parameters:
        parameter data prototype PIP_test0: category=VALUE, sw-calibration-access=READ-WRITE, type=adt_max_count, init-value=constant-reference=ConstantSpecifications/CONST_PIP_test0
    symbol props SymbolProps: symbol=ModeManagement
package /SwComponentTypes/ApplSWC/ApplicationDataTypes
  app type adt_max_count: category=VALUE, compu {phys=raw} "CompuMethod for adt_max_count", range phys 10..200, phys 10..200, phys 10..200, phys 10..200, phys 10..200, phys 10..200, phys 10..200, phys 10..200, phys 10..200, phys 10..200, phys 10..200, phys 10..200, phys 10..200, phys 10..200  # ApplicationDataType for PIP_test0
package /SwComponentTypes/ApplSWC/ConstantSpecifications
  14 x constant specification, all with category=VALUE, value-spec=50:
    CONST_PIP_test0
    CONST_PIP_test0
    CONST_PIP_test1
    CONST_PIP_test1
    CONST_PIP_test2
    CONST_PIP_test2
    CONST_PIP_test3
    CONST_PIP_test3
    CONST_PIP_test5
    CONST_PIP_test5
    CONST_PIP_test6
    CONST_PIP_test6
    CONST_PIP_test7
    CONST_PIP_test7
